# ATSAMRH707F18A register map
Vendor: Microchip Technology; Series: SAMRH707; File version: 0
CPU: CM7 r1p1, little endian, MPU, FPU, double-precision FPU, I-cache, D-cache, ITCM, DTCM, 3 interrupt priority bits, 69 interrupts
Registers are 32-bit, read-write, reset 0x0 unless marked. A register's access mark holds for its fields unless they carry their own. Offsets are from the block's base; [hi:lo] are bit positions; lines under a group give offsets from that group; {n}, {i} and the like mark numbered series; 'fields as' and 'values as' point back to an identical list.

## HEMC
Base 0x40080000
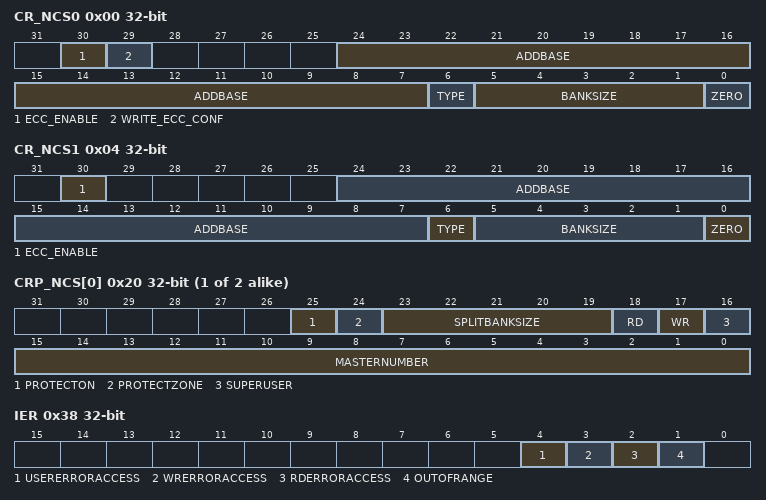
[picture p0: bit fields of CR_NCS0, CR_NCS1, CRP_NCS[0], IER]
0x00 CR_NCS0 — HEMC Control Register NCS 0
  [30] ECC_ENABLE — ECC Protection Enable
  [29] WRITE_ECC_CONF — ECC Configuration Protection Enable
  [24:7] ADDBASE — relative base address of NCS area
  [6] TYPE — type of memory used
  [5:1] BANKSIZE
    0=_8KB (8Kbytes); 1=_16KB (16Kbytes); 2=_32KB (32Kbytes); 3=_64KB (64Kbytes); 4=_128KB (128Kbytes); 5=_256KB (256Kbytes); 6=_512KB (512Kbytes); 7=_1MB (1Mbytes); 8=_2MB (2Mbytes); 31=NOT_USED
  [0] ZERO — fixed to 0
0x04 CR_NCS1 — HEMC Control Register NCS 1
  [30] ECC_ENABLE — ECC Protection Enable
  [24:7] ADDBASE — relative base address of NCS area
  [6] TYPE — type of memory used
  [5:1] BANKSIZE
    values as CR_NCS0.BANKSIZE
  [0] ZERO — fixed to 0
0x18 CTRL — HEMC Polarity Control register
  [0] POL — External control buffer active polarity
{0x20+4i} CRP_NCS[{i}] (i=0..1) — HEMC Control Register Protection NCS
  [25] PROTECTON — protection activation
  [24] PROTECTZONE — select area protected
  [23:19] SPLITBANKSIZE — bank size internal separation
  [18] RD — Read Access
  [17] WR — Write Access
  [16] SUPERUSER — User or Superuser access
  [15:0] MASTERNUMBER — Master Number ID
0x38 IER wo — HEMC Interrupt Enable Register
  [4] USERERRORACCESS — user or superuser access error
  [3] WRERRORACCESS — write access error
  [2] RDERRORACCESS — read access error
  [1] OUTOFRANGE
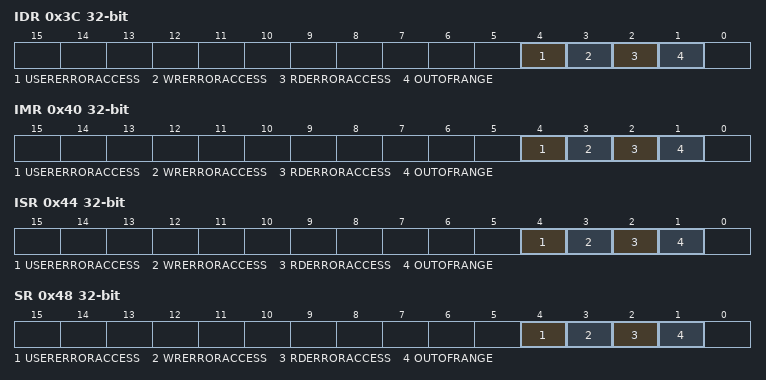
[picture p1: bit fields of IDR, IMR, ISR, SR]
0x3C IDR wo — HEMC Interrupt Disable Register
  fields as IER
0x40 IMR ro — HEMC Interrupt Mask Register
  fields as IER
0x44 ISR ro — HEMC Interrupt Status Register
  [4] USERERRORACCESS — User or SuperUser Error Access
  [3] WRERRORACCESS — Write access error
  [2] RDERRORACCESS — read access error
  [1] OUTOFRANGE
0x48 SR ro — HEMC Status Register
  [4] USERERRORACCESS — User or SuperUser Error Access
  [3] WRERRORACCESS — Write access error
  [2] RDERRORACCESS — Read access error
  [1] OUTOFRANGE
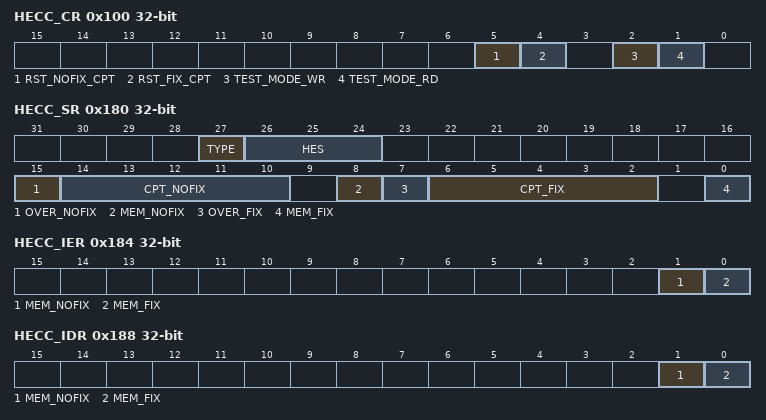
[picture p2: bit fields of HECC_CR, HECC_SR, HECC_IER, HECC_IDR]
0x100 HECC_CR — HECC Control Register Channel 0 (HSMC)
  [5] RST_NOFIX_CPT — reset the un-fixable error counter
  [4] RST_FIX_CPT — reset the fixable error counter
  [2] TEST_MODE_WR — test mode of ECC protection - write mode
  [1] TEST_MODE_RD — test mode of ECC protection - read mode
0x140 HECC_TESTCB — HECC Test mode Register Channel 0 (HSMC)
  [15:0] TCB1 — test check bit (16 bit)
0x180 HECC_SR ro — HECC Status Register
  [27] TYPE — write or read access
  [26:24] HES — Hardware Error Size
  [15] OVER_NOFIX — counter overflow
  [14:10] CPT_NOFIX — 5 bits counter
  [8] MEM_NOFIX — Un-fixable error status
  [7] OVER_FIX — counter overflow
  [6:2] CPT_FIX — 5 bits counter
  [0] MEM_FIX — Fixable error status
0x184 HECC_IER wo — HECC Interrupt Enable Register
  [1] MEM_NOFIX — Un-fixable error
  [0] MEM_FIX — Fixable error
0x188 HECC_IDR wo — HECC Interrupt Disable Register
  [1] MEM_NOFIX — un-fixable error
  [0] MEM_FIX — fixable error
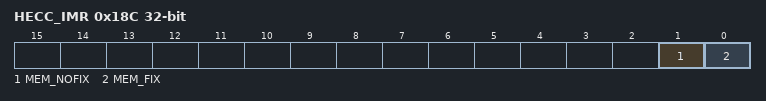
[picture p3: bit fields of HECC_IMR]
0x18C HECC_IMR ro — HECC Interrupt Mask Register
  [1] MEM_NOFIX — un-fixable error
  [0] MEM_FIX — fixable error
0x190 HECC_FAILAR ro — HECC Fail address register
  [31:0] ADDRESS — address of the error detected
0x194 HECC_FAILDR ro — HECC Fail data register
  [31:0] DATA — Data error detected

## HSMC — Harden Static Memory Controller
Base 0x40081000
{0x0+0x10*i} HSMC_CS[{i}] (i=0..1) group
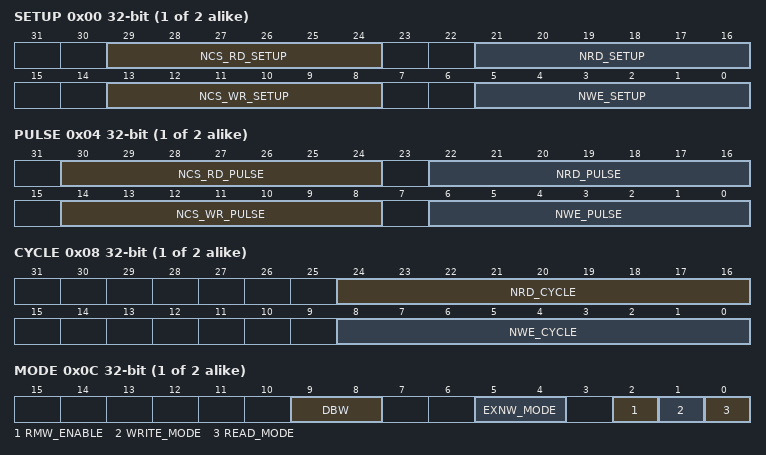
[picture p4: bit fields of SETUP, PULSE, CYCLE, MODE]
  0x00 SETUP — HSMC Setup Register
    [29:24] NCS_RD_SETUP — NCS Setup Length in READ Access
    [21:16] NRD_SETUP — NRD Setup Length
    [13:8] NCS_WR_SETUP — NCS Setup Length in WRITE Access
    [5:0] NWE_SETUP — NWE Setup Length
  0x04 PULSE — HSMC Pulse Register
    [30:24] NCS_RD_PULSE — NCS Pulse Length in READ Access
    [22:16] NRD_PULSE — NRD Pulse Length
    [14:8] NCS_WR_PULSE — NCS Pulse Length in WRITE Access
    [6:0] NWE_PULSE — NWE Pulse Length
  0x08 CYCLE — HSMC Cycle Register
    [24:16] NRD_CYCLE — Total Read Cycle Length
    [8:0] NWE_CYCLE — Total Write Cycle Length
  0x0C MODE — HSMC Mode Register
    [9:8] DBW — Data Bus Width
      0=_8_BIT (8-bit Data Bus)
    [5:4] EXNW_MODE — NWAIT Mode
      0=DISABLED (Disabled-The NWAIT input signal is ignored on the corresponding chip select.); 2=FROZEN (Frozen Mode-If asserted, the NWAIT signal freezes the current read or write cycle. After deassertion, the read/write cycle is resumed from the point where it was stopped.); 3=READY (Ready Mode-The NWAIT signal indicates the availability of the external device at the end of the pulse of the controlling read or write signal, to complete the access. If high, the access normally completes. If low, the access is extended until NWAIT returns high.)
    [2] RMW_ENABLE — Read-Modify Write enable
    [1] WRITE_MODE
    [0] READ_MODE
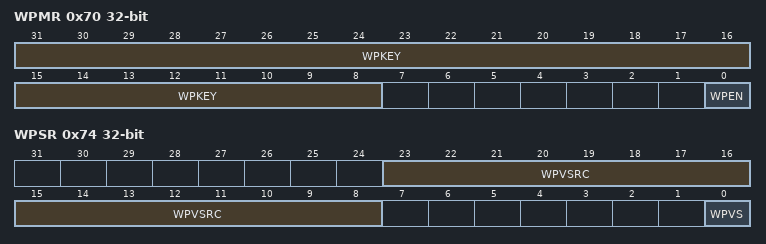
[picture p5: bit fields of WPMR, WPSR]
0x70 WPMR — HSMC Write Protection Mode Register
  [31:8] WPKEY — Write Protection Key
    0x534D43=PASSWD (Writing any other value in this field aborts the write operation of the WPEN bit. Always reads as 0.)
  [0] WPEN — Write Protect Enable
0x74 WPSR ro — HSMC Write Protection Status Register
  [23:8] WPVSRC — Write Protection Violation Source
  [0] WPVS — Write Protection Violation Status
